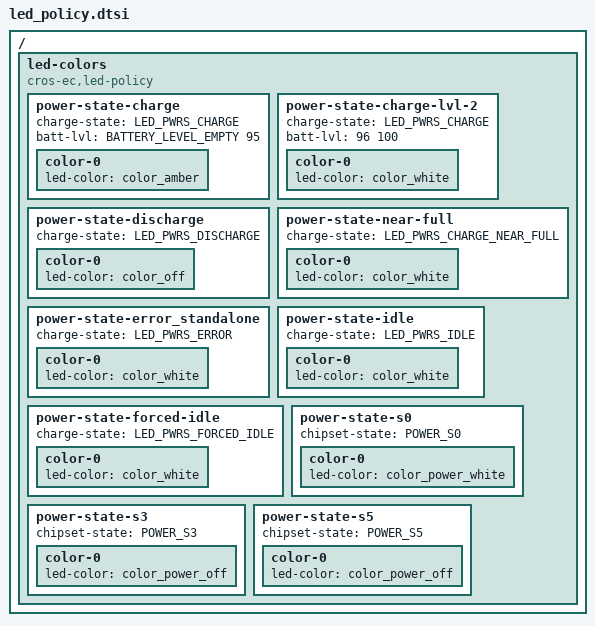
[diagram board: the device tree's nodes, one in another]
#include <dt-bindings/battery.h>

/ {
	led-colors {
		compatible = "cros-ec,led-policy";

		power-state-charge {
			charge-state = "LED_PWRS_CHARGE";
			/* Battery percent range (>= 0, < 96) */
			batt-lvl = <BATTERY_LEVEL_EMPTY 95>;
			color-0 {
				led-color = <&color_amber>;
			};
		};

		power-state-charge-lvl-2 {
			charge-state = "LED_PWRS_CHARGE";
			/* Battery percent range (>= 96%, <= 100%) */
			batt-lvl = <96 100>;

			color-0 {
				led-color = <&color_white>;
			};
		};

		power-state-discharge {
			charge-state = "LED_PWRS_DISCHARGE";

			color-0 {
				led-color = <&color_off>;
			};
		};

		power-state-near-full {
			charge-state = "LED_PWRS_CHARGE_NEAR_FULL";
			/* Battery percent range (>= 97, <= 100) */
		
			color-0 {
				led-color = <&color_white>;
			};
		};

		power-state-error_standalone {
			charge-state = "LED_PWRS_ERROR";

			color-0 {
				led-color = <&color_white>;
			};
		};

		power-state-idle {
			charge-state = "LED_PWRS_IDLE";

			color-0 {
				led-color = <&color_white>;
			};
		};

		power-state-forced-idle {
			charge-state = "LED_PWRS_FORCED_IDLE";

			color-0 {
				led-color = <&color_white>;
			};
		};

		power-state-s0 {
			chipset-state = "POWER_S0";

			color-0 {
				led-color = <&color_power_white>;
			};
		};

		power-state-s3 {
			chipset-state = "POWER_S3";

			color-0 {
				led-color = <&color_power_off>;
			};
		};

		power-state-s5 {
			chipset-state = "POWER_S5";

			color-0 {
				led-color = <&color_power_off>;
			};
		};
	};
};
